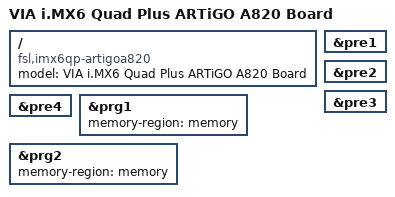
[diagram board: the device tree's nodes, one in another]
/*
 * Copyright 2014-2018 VIA Technologies, Inc.
 * Copyright (C) 2015 Freescale Semiconductor, Inc.
 *
 * This program is free software; you can redistribute it and/or modify
 * it under the terms of the GNU General Public License version 2 as
 * published by the Free Software Foundation.
 */

/dts-v1/;

#include "imx6qp.dtsi"
#include "imx6qdl-artigoa820.dtsi"

/ {
	model = "VIA i.MX6 Quad Plus ARTiGO A820 Board";
	compatible = "fsl,imx6qp-artigoa820", "fsl,imx6qp";
};

&pre1 {
	status = "okay";
};

&pre2 {
	status = "okay";
};

&pre3 {
	status = "okay";
};

&pre4 {
	status = "okay";
};

&prg1 {
	memory-region = <&memory>;
	status = "okay";
};

&prg2 {
	memory-region = <&memory>;
	status = "okay";
};
